# GPMC_GPMC_3B000000h register map
Vendor: Texas Instruments
Peripheral module from a debugger description file (folder am62D).
Registers are 32-bit, access per field, reset 0x0 unless marked. A register's access mark holds for its fields unless they carry their own. Offsets are as the file gives them; lines under a group give offsets from that group; [hi:lo] are bit positions; {n}, {i} and the like mark numbered series; 'fields as' and 'values as' point back to an identical list; <NAME> marks a mode.

## gpmc
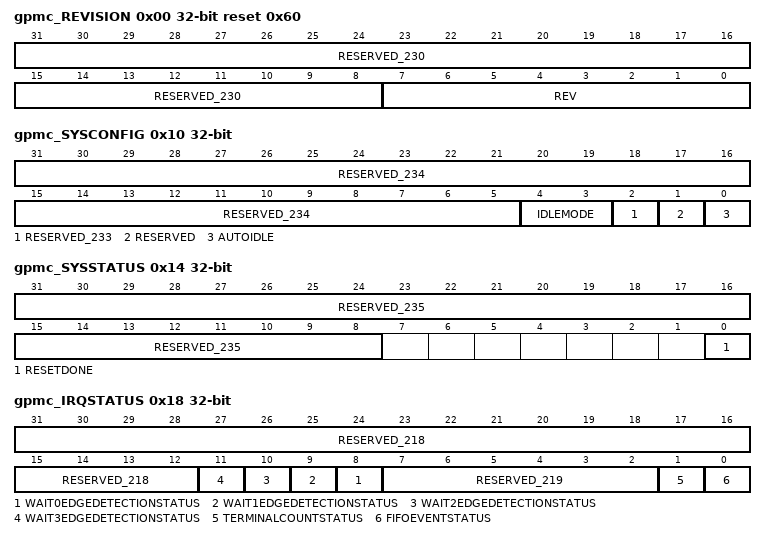
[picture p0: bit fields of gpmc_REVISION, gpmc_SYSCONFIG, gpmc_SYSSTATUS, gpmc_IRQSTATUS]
0x00 gpmc_REVISION ro reset 0x60 — This register contains the IP revision code
  [31:8] RESERVED_230 — Reads returns 0
  [7:0] REV — IP revision[7:4]Major revision[3:0]Minor revisionExamples: 0x10 for 1.0, 0x21 for 2.1 Reset Source: func_mod_g_arst_n
0x10 gpmc_SYSCONFIG — This register controls the various parameters of the OCP interface
  [31:5] RESERVED_234 ro — Write 0's for future compatibility Reads return 0
  [4:3] IDLEMODE rw — 0 Force-idle. An idle request is acknowledged unconditionally1 No-idle. An idle request is never acknowledged2 Smart-idle. Acknowledgement to an idle request is given based on the internal activity of the module3 reserved do not use
  [2] RESERVED_233 ro — Write 0 for future compatibility Reads returns 0
  [1] RESERVED rw — This bit must be kept 0 for normal functioning of the IP. Do not set this bit to 1 0 Normal mode1 The module is reset
  [0] AUTOIDLE rw — Internal OCP clock gating strategy 0 OCP clock is free-running1 Automatic OCP clock gating strategy is applied, based on the OCP interface activity
0x14 gpmc_SYSSTATUS ro — This register provides status information about the module, excluding the interrupt status information
  [31:8] RESERVED_235 — Reads returns 0
  [0] RESETDONE — Internal reset monitoring 0 Internal module reset in on-going1 Reset completed
0x18 gpmc_IRQSTATUS access not given — This interrupt status register regroups all the status of the module internal events that can generate an interrupt.
  [31:12] RESERVED_218 ro — Write 0's for future compatibility. Read returns 0
  [n+8] WAIT{n}EDGEDETECTIONSTATUS (n=0..3) — Status of the Wait{n} Edge Detection interrupt 0 Read 0: A transition on WAIT{n} input pin has not been detected0 Write 0: Wait{n}EdgeDetection status bit unchanged1 Read 1: A transition on WAIT{n} input pin has been detected1 Write 1: Wait{n}EdgeDetection status bit is reset (access R/W1TC)
  [7:2] RESERVED_219 ro — Write 0's for future compatibility. Read returns 0
  [1] TERMINALCOUNTSTATUS — Status of the TerminalCountEvent interrupt 0 Read 0: Indicates that CountValue is greater than 00 Write 0: TerminalCountEvent status bit unchanged1 Read 1: Indicates that CountValue is equal to 01 Write 1: TerminalCountEvent status bit is reset (access R/W1TC)
  [0] FIFOEVENTSTATUS — Status of the FIFOEvent interrupt 0 Read 0: Indicates than less than FIFOThreshold bytes are available in prefetch mode and less than FIFOThreshold bytes free places are available in write posting mode.0 Write 0: FIFOEvent status bit unchanged1 Read 1: Indicates than at least FIFOThreshold bytes are available in prefetch mode and at least FIFOThreshold bytes free places are available in write posting mode.1 Write 1: FIFOEvent status bit is reset (access R/W1TC)
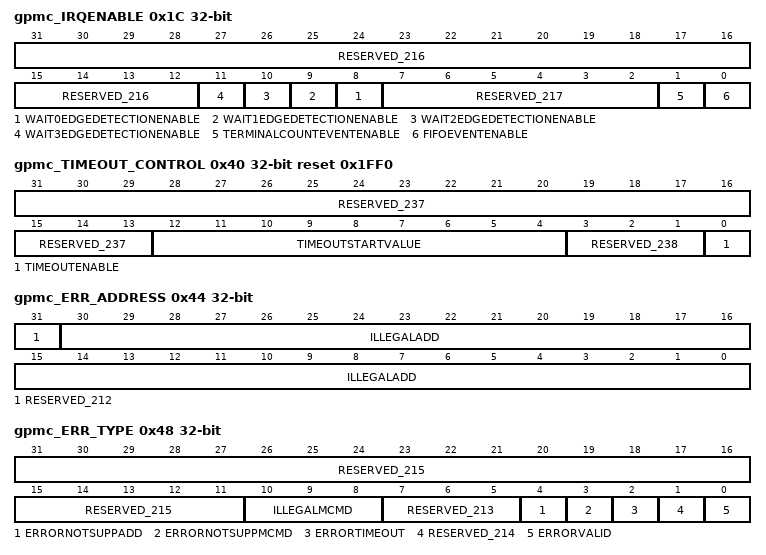
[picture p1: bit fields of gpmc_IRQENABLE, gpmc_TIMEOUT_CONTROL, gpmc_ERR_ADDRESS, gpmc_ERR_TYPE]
0x1C gpmc_IRQENABLE — The interrupt enable register allows to mask/unmask the module internal sources of interrupt, on a event-by-event basis.
  [31:12] RESERVED_216 ro — Write 0's for future compatibility. Read returns 0
  [n+8] WAIT{n}EDGEDETECTIONENABLE rw (n=0..3) — Enables the Wait{n} Edge Detection interrupt 0 Wait{n}EdgeDetection interrupt is masked1 Wait{n}EdgeDetection event generates an interrupt if occurs
  [7:2] RESERVED_217 ro — Write 0's for future compatibility. Read returns 0
  [1] TERMINALCOUNTEVENTENABLE rw — Enables TerminalCountEvent interrupt issuing in pre-fetch or write posting mode 0 TerminalCountEvent interrupt is masked1 TerminalCountEvent interrupt is not masked
  [0] FIFOEVENTENABLE rw — Enables the FIFOEvent interrupt 0 FIFOEvent interrupt is masked1 FIFOEvent interrupt is not masked
0x40 gpmc_TIMEOUT_CONTROL reset 0x1FF0 — The GPMC_TIMEOUT_CONTROL register allows the user to set the start value of the timeout counter
  [31:13] RESERVED_237 ro — Write 0's for future compatibility. Read returns 0
  [12:4] TIMEOUTSTARTVALUE rw — Start value of the time-out counter [0x000 corresponds to 0 GPMC.FCLK cycle, 0x001 corresponds to 1 GmpcClk cycle, &, 0x1FF corresponds to 511 GPMC.FCLK cyles.] Reset Source: func_mod_g_arst_n
  [3:1] RESERVED_238 ro — Write 0's for future compatibility. Read returns 0
  [0] TIMEOUTENABLE rw — Enable bit of the TimeOut feature 0 TimeOut feature is disabled1 TimeOut feature is enabled
0x44 gpmc_ERR_ADDRESS ro — The GPMC_ERR_ADDRESS register stores the address of the illegal access when an error occurs
  [31] RESERVED_212 — Write 0's for future compatibility. Read returns 0
  [30:0] ILLEGALADD — Address of illegal access : A30[0 for memory region, 1 for GPMC register region] and A29-A0[1 GBytes maximum] Reset Source: func_mod_g_arst_n
0x48 gpmc_ERR_TYPE access not given — The GPMC_ERR_TYPE register stores the type of error when an error occurs
  [31:11] RESERVED_215 ro — Write 0's for future compatibility. Read returns 0
  [10:8] ILLEGALMCMD ro — System Command of the transaction that caused the error Reset Source: func_mod_g_arst_n
  [7:5] RESERVED_213 ro — Write 0's for future compatibility. Read returns 0
  [4] ERRORNOTSUPPADD ro — Not supported Address error 0 No error occurs1 The error is due to a non supported Address
  [3] ERRORNOTSUPPMCMD ro — Not supported Command error 0 No error occurs1 The error is due to a non supported Command
  [2] ERRORTIMEOUT ro — Time-out error 0 No error occurs1 The error is due to a time out
  [1] RESERVED_214 ro — Write 0's for future compatibility. Read returns 0
  [0] ERRORVALID — Error validity status - Must be explicitely cleared with a write 1 transaction 0 All error fields no longer valid1 Error detected and logged in the other error fields (access R/W1TC)
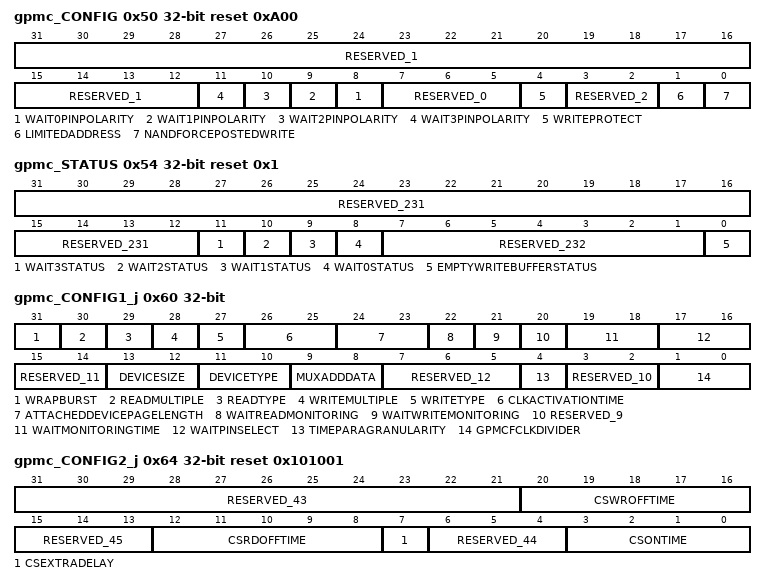
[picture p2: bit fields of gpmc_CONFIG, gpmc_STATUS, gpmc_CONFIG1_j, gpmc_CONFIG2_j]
0x50 gpmc_CONFIG reset 0xA00 — The configuration register allows global configuration of the GPMC
  [31:12] RESERVED_1 ro — Write 0's for future compatibility. Read returns 0
  [n+8] WAIT{n}PINPOLARITY rw (n=0..3) — Selects the polarity of input pin WAIT{n} 0 WAIT{n} active low1 WAIT{n} active high
  [7:5] RESERVED_0 ro — Write 0's for future compatibility. Read returns 0
  [4] WRITEPROTECT rw — Controls the WP output pin level 0 WP output pin is low1 WP output pin is high
  [3:2] RESERVED_2 ro — Write 0's for future compatibility. Read returns 0
  [1] LIMITEDADDRESS rw — Limited Address device support 0 No effect1 A26-A11 are not modified during an external memory access.
  [0] NANDFORCEPOSTEDWRITE rw — Enables the Force Posted Write feature to NAND Cmd/Add/Data location 0 Disables Force Posted Write1 Enables Force Posted Write
0x54 gpmc_STATUS ro reset 0x1 — The status register provides global status bits of the GPMC
  [31:12] RESERVED_231 — Write 0's for future compatibility. Read returns 0
  [11] WAIT3STATUS — Is a copy of input pin WAIT3. [Reset value is WAIT3 input pin sampled at IC reset] 0 WAIT3 de-asserted1 WAIT3 asserted
  [10] WAIT2STATUS — Is a copy of input pin WAIT2. [Reset value is WAIT2 input pin sampled at IC reset] 0 WAIT2 de-asserted1 WAIT2 asserted
  [9] WAIT1STATUS — Is a copy of input pin WAIT1. [Reset value is WAIT1 input pin sampled at IC reset] 0 WAIT1 de-asserted1 WAIT1 asserted
  [8] WAIT0STATUS — Is a copy of input pin WAIT0. [Reset value is WAIT0 input pin sampled at IC reset] 0 WAIT0 de-asserted1 WAIT0 asserted
  [7:1] RESERVED_232 — Write 0's for future compatibility Reads returns 0
  [0] EMPTYWRITEBUFFERSTATUS — Stores the empty status of the write buffer 0 Write Buffer is not empty1 Write Buffer is empty
0x60 gpmc_CONFIG1_j — The configuration 1 register sets signal control parameters per chip select
  [31] WRAPBURST rw — Enables the wrapping burst capability. Must be set if the attached device is configured in wrapping burst 0 Synchronous wrapping burst not supported1 Synchronous wrapping burst supported
  [30] READMULTIPLE rw — Selects the read single or multiple access 0 single access1 multiple access (burst if synchonous, page if asynchronous)
  [29] READTYPE rw — Selects the read mode operation 0 Read Asynchronous1 Read Synchronous
  [28] WRITEMULTIPLE rw — Selects the write single or multiple access 0 single access1 multiple access (burst if synchonous, considered as single if asynchronous)
  [27] WRITETYPE rw — Selects the write mode operation 0 Write Asynchronous1 Write Synchronous
  [26:25] CLKACTIVATIONTIME rw — Output GPMC.CLK activation time 0 First rising edge of GPMC.CLK at Start Access Time1 First rising edge of GPMC.CLK one GPMC.FCLK cycle after Start Access Time2 First rising edge of GPMC.CLK two GPMC.FCLK cycles after Start Access Time3 not defined
  [24:23] ATTACHEDDEVICEPAGELENGTH rw — Specifies the attached device page [burst] length 0 4 Words1 8 Words2 16 Words3 32 Words
  [22] WAITREADMONITORING rw — Selects the Wait monitoring configuration for Read accesses [Reset value is BOOTWAITEN input pin sampled at IC reset] 0 Wait pin is not monitored for read accesses1 Wait pin is monitored for read accesses
  [21] WAITWRITEMONITORING rw — Selects the Wait monitoring configuration for Write accesses 0 Wait pin is not monitored for write accesses1 Wait pin is monitored for write accesses
  [20] RESERVED_9 ro — Write 0's for future compatibility. Read returns 0
  [19:18] WAITMONITORINGTIME rw — Selects input pin Wait monitoring time 0 Wait pin is monitored with valid data1 Wait pin is monitored one GPMC.CLK cycle before valid data2 Wait pin is monitored two GPMC.CLK cycle before valid data3 not defined
  [17:16] WAITPINSELECT rw — Selects the input WAIT pin for this chip select [Reset value is BOOTWAITSELECT input pin sampled at IC reset for CS0 and 0 for CS1-7] 0 Wait input pin is WAIT01 Wait input pin is WAIT12 Wait input pin is WAIT23 Wait input pin is WAIT3
  [15:14] RESERVED_11 ro — Write 0's for future compatibility. Read returns 0
  [13:12] DEVICESIZE rw — Selects the device size attached [Reset value is BOOTDEVICESIZE input pin sampled at IC reset for CS0 and 01 for CS1-7] 0 8 bit1 16 bit2 32 bit3 reserved
  [11:10] DEVICETYPE rw — Selects the attached device type 0 NOR Flash, pSRAM, asynchronous devices1 reserved2 NAND Flash stream mode3 reserved
  [9:8] MUXADDDATA rw — Enables the Address and data multiplexed protocol [Reset value is CS0MUXDEVICE input pin sampled at IC reset for CS0 and 0 for CS1-7] 0 Non Multiplexed attached device1 AAD-Mux protocol device2 Address and data multiplexed attached device3 Reserved
  [7:5] RESERVED_12 ro — Write 0's for future compatibility. Read returns 0
  [4] TIMEPARAGRANULARITY rw — Signals timing latencies scalar factor [Rd/WRCycleTime, AccessTime, PageBurstAccessTime, CSOnTime, CSRd/WrOffTime, ADVOnTime, ADVRd/WrOffTime, OEOnTime, OEOffTime, WEOnTime, WEOffTime, Cycle2CycleDelay, BusTurnAround, TimeOutStartValue] 0 x1 latencies1 x2 latencies
  [3:2] RESERVED_10 ro — Write 0's for future compatibility. Read returns 0
  [1:0] GPMCFCLKDIVIDER rw — Divides the GPMC.FCLK clock 0 GPMC.CLK frequency = GPMC.FCLK frequency1 GPMC.CLK frequency = GPMC.FCLK frequency / 22 GPMC.CLK frequency = GPMC.FCLK frequency / 33 GPMC.CLK frequency = GPMC.FCLK frequency /4
0x64 gpmc_CONFIG2_j reset 0x101001 — Chip-select signal timing parameter configuration
  [31:21] RESERVED_43 ro — Write 0's for future compatibility Reads returns 0
  [20:16] CSWROFFTIME rw — CS# de-assertion time from start cycle time for write accesses [0x00 corresponds to 0 GPMC.FCLK cycle, 0x01 corresponds to 1 GPMC.FCLK cycle, &, 0x1F corresponds to 31 GPMC.FCLK cycles] Reset Source: func_mod_g_arst_n
  [15:13] RESERVED_45 ro — Write 0's for future compatibility. Read returns 0
  [12:8] CSRDOFFTIME rw — CS# de-assertion time from start cycle time for read accesses [0x00 corresponds to 0 GPMC.FCLK cycle, 0x01 corresponds to 1 GPMC.FCLK cycle, &, 0x1F corresponds to 31 GPMC.FCLK cycles] Reset Source: func_mod_g_arst_n
  [7] CSEXTRADELAY rw — CS# Add Extra Half GPMC.FCLK cycle 0 CS# Timing control signal is not delayed1 CS# Timing control signal is delayed of half GPMC.FCLK clock cycle
  [6:4] RESERVED_44 ro — Write 0's for future compatibility. Read returns 0
  [3:0] CSONTIME rw — CS# assertion time from start cycle time [0x0 corresponds to 0 GPMC.FCLK cycle, 0x1 corresponds to 1 GPMC.FCLK cycle, &, 0xF corresponds to 15 GPMC.FCLK cycles] Reset Source: func_mod_g_arst_n
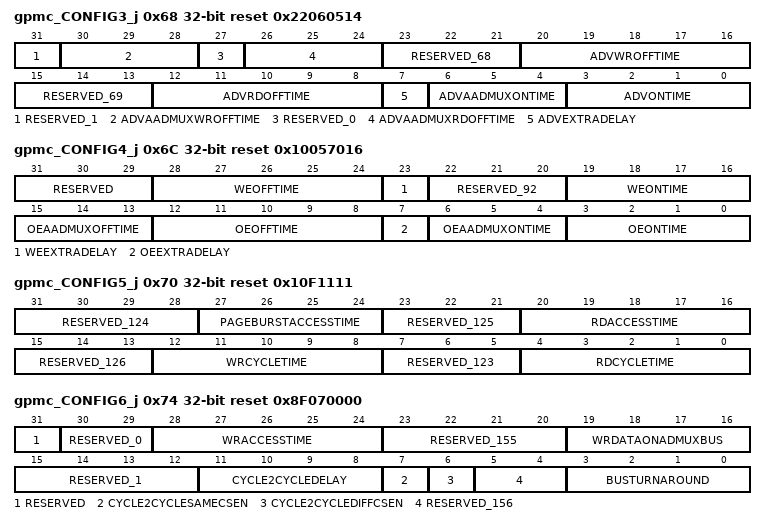
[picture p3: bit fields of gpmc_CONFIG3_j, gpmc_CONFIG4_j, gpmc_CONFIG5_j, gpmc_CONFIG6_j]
0x68 gpmc_CONFIG3_j reset 0x22060514 — ADV# signal timing parameter configuration
  [31] RESERVED_1 ro — Write 0's for future compatibility. Read returns 0
  [30:28] ADVAADMUXWROFFTIME rw — ADV# de-assertion for first address phase when using the AAD-Mux protocol Reset Source: func_mod_g_arst_n
  [27] RESERVED_0 ro — Write 0's for future compatibility. Read returns 0
  [26:24] ADVAADMUXRDOFFTIME rw — ADV# assertion for first address phase when using the AAD-Mux protocol Reset Source: func_mod_g_arst_n
  [23:21] RESERVED_68 ro — Write 0's for future compatibility. Read returns 0
  [20:16] ADVWROFFTIME rw — ADV# de-assertion time from start cycle time for write accesses [0x00 corresponds to 0 GPMC.FCLK cycle, 0x01 corresponds to 1 GPMC.FCLK cycle, &, 0x1F corresponds to 31 GPMC.FCLK cycles] Reset Source: func_mod_g_arst_n
  [15:13] RESERVED_69 ro — Write 0's for future compatibility. Read returns 0
  [12:8] ADVRDOFFTIME rw — ADV# de-assertion time from start cycle time for read accesses[0x00 corresponds to 0 GPMC.FCLK cycle, 0x01 corresponds to 1 GPMC.FCLK cycle, &, 0x1F corresponds to 31 GPMC.FCLK cycles] Reset Source: func_mod_g_arst_n
  [7] ADVEXTRADELAY rw — ADV# Add Extra Half GPMC.FCLK cycle 0 ADV# Timing control signal is not delayed1 ADV# Timing control signal is delayed of half GPMC.FCLK clock cycle
  [6:4] ADVAADMUXONTIME rw — ADV# assertion for first address phase when using the AAD-Mux protocol Reset Source: func_mod_g_arst_n
  [3:0] ADVONTIME rw — ADV# assertion time from start cycle time [0x0 corresponds to 0 GPMC.FCLK cycle, 0x1 corresponds to 1 GPMC.FCLK cycle, &, 0xF corresponds to 15 GPMC.FCLK cycles] Reset Source: func_mod_g_arst_n
0x6C gpmc_CONFIG4_j reset 0x10057016 — WE# and OE# signals timing parameter configuration
  [31:29] RESERVED ro — Write 0's for future compatibility. Read returns 0
  [28:24] WEOFFTIME rw — WE# de-assertion time from start cycle time [0x00 corresponds to 0 GPMC.FCLK cycle, 0x01 corresponds to 1 GPMC.FCLK cycle, &, 0x1F corresponds to 31 GPMC.FCLK cycles] Reset Source: func_mod_g_arst_n
  [23] WEEXTRADELAY rw — WE# Add Extra Half GPMC.FCLK cycle 0 WE# Timing control signal is not delayed1 WE# Timing control signal is delayed of half GPMC.FCLK clock cycle
  [22:20] RESERVED_92 ro — Write 0's for future compatibility. Read returns 0
  [19:16] WEONTIME rw — WE# assertion time from start cycle time [0x0 corresponds to 0 GPMC.FCLK cycle, 0x1 corresponds to 1 GPMC.FCLK cycle, &, 0xF corresponds to 15 GPMC.FCLK cycles] Reset Source: func_mod_g_arst_n
  [15:13] OEAADMUXOFFTIME rw — OE# de-assertion time for the first address phase in an AAD-Mux access Reset Source: func_mod_g_arst_n
  [12:8] OEOFFTIME rw — OE# de-assertion time from start cycle time [0x00 corresponds to 0 GPMC.FCLK cycle, 0x01 corresponds to 1 GPMC.FCLK cycle, &, 0x1F corresponds to 31 GPMC.FCLK cycles] Reset Source: func_mod_g_arst_n
  [7] OEEXTRADELAY rw — OE# Add Extra Half GPMC.FCLK cycle 0 OE# Timing control signal is not delayed1 OE# Timing control signal is delayed of half GPMC.FCLK clock cycle
  [6:4] OEAADMUXONTIME rw — OE# assertion time for the first address phase in an AAD-Mux access Reset Source: func_mod_g_arst_n
  [3:0] OEONTIME rw — OE# assertion time from start cycle time [0x0 corresponds to 0 GPMC.FCLK cycle, 0x1 corresponds to 1 GPMC.FCLK cycle, &, 0xF corresponds to 15 GPMC.FCLK cycles] Reset Source: func_mod_g_arst_n
0x70 gpmc_CONFIG5_j reset 0x10F1111 — RdAccessTime and CycleTime timing parameters configuration
  [31:28] RESERVED_124 ro — Write 0's for future compatibility. Read returns 0
  [27:24] PAGEBURSTACCESSTIME rw — Delay between successive words in a multiple access [0x0 corresponds to 0 GPMC.FCLK cycle, 0x1 corresponds to 1 GPMC.FCLK cycle, &, 0xF corresponds to 15 GPMC.FCLK cycles] Reset Source: func_mod_g_arst_n
  [23:21] RESERVED_125 ro — Write 0's for future compatibility. Read returns 0
  [20:16] RDACCESSTIME rw — Delay between start cycle time and first data valid [0x00 corresponds to 0 GPMC.FCLK cycle, 0x01 corresponds to 1 GPMC.FCLK cycle, &, 0x1F corresponds to 31 GPMC.FCLK cycles] Reset Source: func_mod_g_arst_n
  [15:13] RESERVED_126 ro — Write 0's for future compatibility Reads returns 0
  [12:8] WRCYCLETIME rw — Total write cycle time [0x00 corresponds to 0 GPMC.FCLK cycle, 0x01 corresponds to 1 GPMC.FCLK cycle, &, 0x1F corresponds to 31 GPMC.FCLK cycles] Reset Source: func_mod_g_arst_n
  [7:5] RESERVED_123 ro — Write 0's for future compatibility. Read returns 0
  [4:0] RDCYCLETIME rw — Total read cycle time [0x00 corresponds to 0 GPMC.FCLK cycle, 0x01 corresponds to 1 GPMC.FCLK cycle, &, 0x1F corresponds to 31 GPMC.FCLK cycles] Reset Source: func_mod_g_arst_n
0x74 gpmc_CONFIG6_j reset 0x8F070000 — WrAccessTime, WrDataOnADmuxBus, Cycle2Cycle and BusTurnAround parameters configuration
  [31] RESERVED rw — TI Internal use - Do not modify
  [30:29] RESERVED_0 ro — Write 0's for future compatibility. Read returns 0
  [28:24] WRACCESSTIME rw — Delay from StartAccessTime to the GPMC.FCLK rising edge corresponding the the GPMC.CLK rising edge used by the attached memory for the first data capture [0x00 corresponds to 0 GPMC.FCLK cycle, 0x01 corresponds to 1 GPMC.FCLK cycle, &, 0x1F corresponds to 31 GPMC.FCLK cycles] Reset Source: func_mod_g_arst_n
  [23:20] RESERVED_155 ro — Write 0's for future compatibility. Read returns 0
  [19:16] WRDATAONADMUXBUS rw — Specifies on which GPMC.FCLK rising edge the first data of the synchronous burst write is driven in the add/data mux bus Reset Source: func_mod_g_arst_n
  [15:12] RESERVED_1 ro — Write 0's for future compatibility. Read returns 0
  [11:8] CYCLE2CYCLEDELAY rw — Chip select high pulse delay between two successive accesses [0x0 corresponds to 0 GPMC.FCLK cycle, 0x1 corresponds to 1 GPMC.FCLK cycle, &, 0xF corresponds to 15 GPMC.FCLK cycles] Reset Source: func_mod_g_arst_n
  [7] CYCLE2CYCLESAMECSEN rw — Add Cycle2CycleDelay between two successive accesses to the same chip-select [any access type] 0 No delay between the two accesses1 Add Cycle2CycleDelay
  [6] CYCLE2CYCLEDIFFCSEN rw — Add Cycle2CycleDelay between two successive accesses to a different chip-select [any access type] 0 No delay between the two accesses1 Add Cycle2CycleDelay
  [5:4] RESERVED_156 ro — Write 0's for future compatibility Reads returns 0
  [3:0] BUSTURNAROUND rw — Bus turn around latency between two successive accesses to the same chip-select [rd to wr] or to a different chip-select [read to read and read to write] [0x0 corresponds to 0 GPMC.FCLK cycle, 0x1 corresponds to 1 GPMC.FCLK cycle, &, 0xF corresponds to 15 GPMC.FCLK cycles] Reset Source: func_mod_g_arst_n
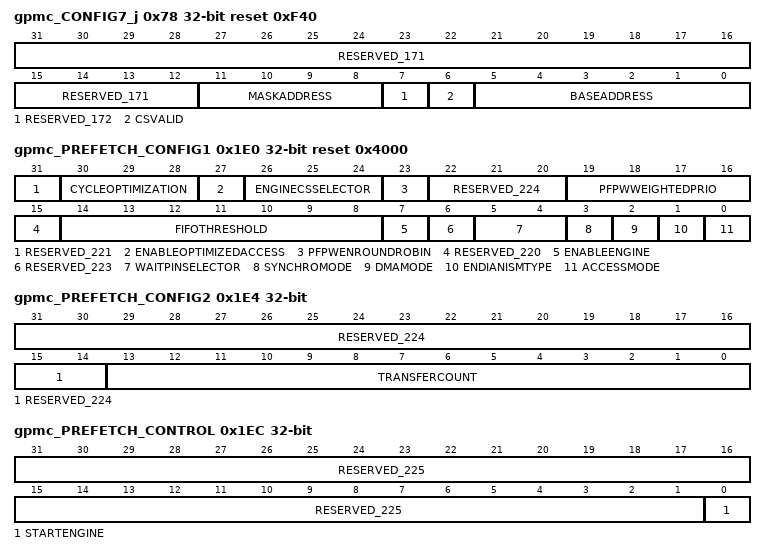
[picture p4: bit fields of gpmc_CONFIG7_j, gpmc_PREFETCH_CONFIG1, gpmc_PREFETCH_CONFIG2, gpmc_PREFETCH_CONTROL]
0x78 gpmc_CONFIG7_j reset 0xF40 — Chip-select address mapping configuration Note: For CS0, the register reset is 0xf40 while for all the other instances CS1-CS7, the reset is 0xf00.
  [31:12] RESERVED_171 ro — Write 0's for future compatibility. Read returns 0
  [11:8] MASKADDRESS rw — Chip-select mask address Reset Source: func_mod_g_arst_n
  [7] RESERVED_172 ro — Write 0's for future compatibility. Read returns 0
  [6] CSVALID rw — Chip-select enable [reset value is 1 for CS0 and 0 for CS1-7] 0 Chip-select disabled1 Chip-select enabled
  [5:0] BASEADDRESS rw — Chip-select base address Reset Source: func_mod_g_arst_n
0x7C gpmc_NAND_COMMAND_j wo — This Register is not a true register, just a address location.
  [31:0] GPMC_NAND_COMMAND_0 — Reset Source: func_mod_g_arst_n
0x80 gpmc_NAND_ADDRESS_j wo — This Register is not a true register, just a address location.
  [31:0] GPMC_NAND_ADDRESS_0 — Reset Source: func_mod_g_arst_n
0x84 gpmc_NAND_DATA_j rw — This Register is not a true register, just a address location.
  [31:0] GPMC_NAND_DATA_0 — Reset Source: func_mod_g_arst_n
0x1E0 gpmc_PREFETCH_CONFIG1 reset 0x4000 — Prefetch engine configuration 1
  [31] RESERVED_221 ro — Write 0's for future compatibility. Read returns 0
  [30:28] CYCLEOPTIMIZATION rw — Define the number of GPMC.FCLK cycles to be substracted from RdCycleTime, WrCycleTime, AccessTime, CSRdOffTime, CSWrOffTime, ADVRdOffTime, ADVWrOffTime, OEOffTime, WEOffTime [0x0 corresponds to 0 GPMC.FCLK cycle, 0x1 corresponds to 1 GPMC.FCLK cycle, &, 0x7 corresponds to 7 GPMC.FCLK cycles] Reset Source: func_mod_g_arst_n
  [27] ENABLEOPTIMIZEDACCESS rw — Enables access cycle optimization 0 Access cycle optimization is disabled1 Access cycle optimization is enabled
  [26:24] ENGINECSSELECTOR rw — Selects the CS where Prefetch Postwrite engine is active [0x0 corresponds toCS0, 0x1 corresponds to CS1, &, 0x7 corresponds to CS7] Reset Source: func_mod_g_arst_n
  [23] PFPWENROUNDROBIN rw — Enables the PFPW RoundRobin arbitration 0 Prefetch Postwrite engine round robin arbitration is disabled1 Prefetch Postwrite engine round robin arbitration is enabled
  [22:20] RESERVED_224 ro — Write 0's for future compatibility. Read returns 0
  [19:16] PFPWWEIGHTEDPRIO rw — When an arbitration occurs between a direct memory access and a PFPW engine access, the direct memory access is always serviced. If the PFPWEnRoundRobin is enabled, 0x0 means : the next access is granted to the PFPW engine, 0x1 means : the two next accesses are granted to the PFPW engine, ..., 0xF means : the 16 next accesses are granted to the PFPW engine. Reset Source: func_mod_g_arst_n
  [15] RESERVED_220 ro — Write 0's for future compatibility. Read returns 0
  [14:8] FIFOTHRESHOLD rw — Selects the maximum number of bytes read from the FIFO or written to the FIFO by the host on a DMA or interrupt request [0x00 corresponds to 0 byte, 0x01 corresponds to 1 byte, &, 0x40 corresponds to 64 bytes] Reset Source: func_mod_g_arst_n
  [7] ENABLEENGINE rw — Enables the Prefetch Postwite engine 0 Prefetch Postwrite engine is disabled1 Prefetch Postwrite engine is enabled
  [6] RESERVED_223 ro — Write 0's for future compatibility. Read returns 0
  [5:4] WAITPINSELECTOR rw — Select which wait pin edge detector should start the engine in synchronized mode 0 Selects Wait0EdgeDetection1 Selects Wait1EdgeDetection2 Selects Wait2EdgeDetection3 Selects Wait3EdgeDetection
  [3] SYNCHROMODE rw — Selects when the engine starts the access to CS 0 Engine starts the access to CS as soon as StartEngine is set1 Engine starts the access to CS as soon as StartEngine is set AND wait to non wait edge detection on the selected wait pin
  [2] DMAMODE rw — Selects interrupt synchronization or DMA request synchronization 0 Interrupt synchronization is enabled. Only interrupt line will be activated on FIFO threshold crossing.1 DMA request synchronization is enabled.A DMA request protocol is used.
  [1] ENDIANISMTYPE rw — Selects endianism for prefetch data [0x0 for Little Endian and 0x1 for Big Endian] Reset Source: func_mod_g_arst_n
  [0] ACCESSMODE rw — Selects pre-fetch read or write posting accesses 0 Pre-fetch read mode1 Write posting mode
0x1E4 gpmc_PREFETCH_CONFIG2 — Prefetch engine configuration 2
  [31:14] RESERVED_224 ro — Write 0's for future compatibility. Read returns 0
  [13:0] TRANSFERCOUNT rw — Selects the number of bytes to be read or written by the engine to the selected CS [0x0000 corresponds to 0 byte, 0x0001 corresponds to 1 byte, &, 0x2000 corresponds to 8 Kbytes] Reset Source: func_mod_g_arst_n
0x1EC gpmc_PREFETCH_CONTROL — Prefetch engine control
  [31:1] RESERVED_225 ro — Write 0's for future compatibility. Read returns 0
  [0] STARTENGINE rw — Resets the FIFO pointer and starts the engine 0 Write 0 stops the engine Read 0: engine is stopped1 Write 1 resets the FIFO pointer to 0x0 in prefetch mode and 0x40 in postwrite mode and starts the engine. Read 1: engine is running
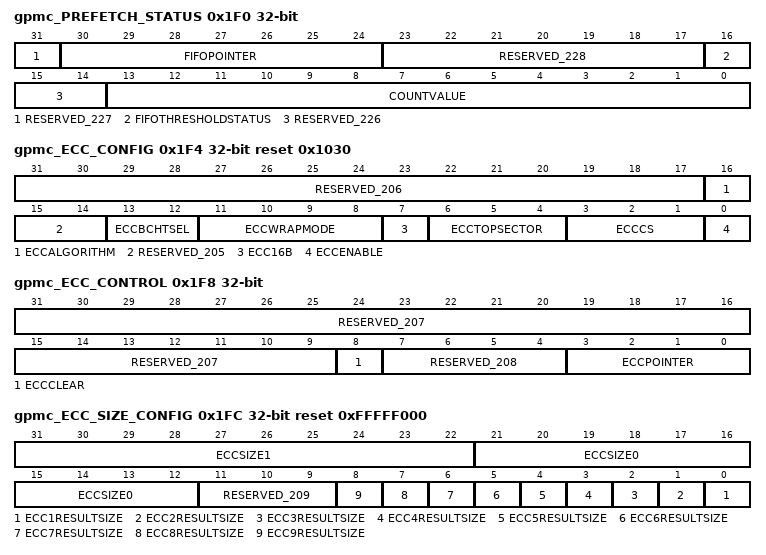
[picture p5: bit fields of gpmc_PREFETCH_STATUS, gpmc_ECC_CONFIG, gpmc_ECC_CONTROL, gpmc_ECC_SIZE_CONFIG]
0x1F0 gpmc_PREFETCH_STATUS ro — Prefetch engine status
  [31] RESERVED_227 — Write 0's for future compatibility. Read returns 0
  [30:24] FIFOPOINTER — Number of available bytes to be read or number of free empty byte places to be written [0x00 corresponds to 0 byte available to be read or 0 free empty place to be written, &, 0x40 corresponds to 64 bytes available to be read or 64 empty places to be written] Reset Source: func_mod_g_arst_n
  [23:17] RESERVED_228 — Write 0's for future compatibility. Read returns 0
  [16] FIFOTHRESHOLDSTATUS — Set when FIFOPointer exceeds FIFOThreshold value 0 FIFOPointer smaller or equal to FIFOThreshold. Writing to this bit has no effect1 FIFOPointer greater than FIFOThreshold. Writing to this bit has no effect
  [15:14] RESERVED_226 — Write 0's for future compatibility. Read returns 0
  [13:0] COUNTVALUE — Number of remaining bytes to be read or to be written by the engine according to the TransferCount value [0x0000 corresponds to 0 byte remaining to be read or to be written, 0x0001 corresponds to 1 byte remaining to be read or to be written, &, 0x2000 corresponds to 8 Kbytes remaining to be read or to be written] Reset Source: func_mod_g_arst_n
0x1F4 gpmc_ECC_CONFIG reset 0x1030 — ECC configuration
  [31:17] RESERVED_206 ro — Write 0's for future compatibility. Read returns 0
  [16] ECCALGORITHM rw — ECC algorithm used0x0: Hamming code0x1: BCH code Reset Source: func_mod_g_arst_n
  [15:14] RESERVED_205 ro — Write 0's for future compatibility. Read returns 0
  [13:12] ECCBCHTSEL rw — Error correction capability used for BCH0x0: up to 4 bits error correction [t = 4]0x1: up to 8 bits error correction [t=8]0x2: up to 16 bits error correction [t=16]0x3: reserved Reset Source: func_mod_g_arst_n
  [11:8] ECCWRAPMODE rw — Spare area organization definition for the BCH algorithm. See the BCH syndrome/parity calculator module functional specification for more details Reset Source: func_mod_g_arst_n
  [7] ECC16B rw — Selects an ECC calculated on 16 columns 0 ECC calculated on 8 columns1 ECC calculated on 16 columns
  [6:4] ECCTOPSECTOR rw — Number of sectors to process with the BCH algorithm0x0: 1 sector [512kB page]0x1: 2 sectors...0x3: 4 sectors [2kB page]...0x7: 8 sectors [4kB page] Reset Source: func_mod_g_arst_n
  [3:1] ECCCS rw — Selects the CS where ECC is computed 0 Chip select 01 Chip select 12 Chip select 23 Chip select 34 Chip select 45 Chip select 56 Chip select 67 Chip select 7
  [0] ECCENABLE rw — Enables the ECC feature 0 ECC disabled1 ECC enabled
0x1F8 gpmc_ECC_CONTROL access not given — ECC control
  [31:9] RESERVED_207 ro — Write 0's for future compatibility. Read returns 0
  [8] ECCCLEAR — Clear all ECC result registers [Reads returns 0 - Writes 1 to this field clear all ECC result registers - Writes 0 are ignored] Reset Source: func_mod_g_arst_n (access R/W1TC)
  [7:4] RESERVED_208 ro — Write 0's for future compatibility. Read returns 0
  [3:0] ECCPOINTER rw — Selects ECC result register [Reads to this field give the dynamic position of the ECC pointer - Writes to this field select the ECC result register where the first ECC computation will be stored]; Other enums: Writing other values disables the ECC engine [ECCEnable bit of GPMC_ECC_CONFIG set to 0] 0 writing 0000 disables the ECC engine (ECCEnable bit of GPMC_ECC_CONFIG set to 0)1 ECC result register 1 is selected2 ECC result register 2 is selected3 ECC result register 3 is selected4 ECC result register 4 is selected5 ECC result register 5 is selected6 ECC result register 6 is selected7 ECC result register 7 is selected8 ECC result register 8 is selected9 ECC result register 9 is selected
0x1FC gpmc_ECC_SIZE_CONFIG reset 0xFFFFF000 — ECC size
  [31:22] ECCSIZE1 rw — Defines ECC size 1 [For Hamming Code: 0x000 corresponds to 2 Bytes, 0x001 corresponds to 4 Bytes, 0x002 corresponds to 6 Bytes, 0x003 corresponds to 8 Bytes, &, 0x0FF corresponds to 512 Bytes. Max supported value is 0x0FF.] [For BCH: 0x000 corresponds to 0 nibbles, 0x001 corresponds to 1 nibble, 0x002 corresponds to 2 nibbles, 0x003 corresponds to 3 nibbles, &, 0x3FF corresponds to 1023 nibbles.] Reset Source: func_mod_g_arst_n
  [21:12] ECCSIZE0 rw — Defines ECC size 0 [For Hamming Code: 0x000 corresponds to 2 Bytes, 0x001 corresponds to 4 Bytes, 0x002 corresponds to 6 Bytes, 0x003 corresponds to 8 Bytes, &, 0x0FF corresponds to 512 Bytes. Max supported value is 0x0FF.] [For BCH: 0x000 corresponds to 0 nibbles, 0x001 corresponds to 1 nibble, 0x002 corresponds to 2 nibbles, 0x003 corresponds to 3 nibbles, &, 0x3FF corresponds to 1023 nibbles.] Reset Source: func_mod_g_arst_n
  [11:9] RESERVED_209 ro — Write 0's for future compatibility. Read returns 0
  [n-1] ECC{n}RESULTSIZE rw (n=1..9) — Selects ECC size for ECC {n} result register 0 ECCSize0 is selected1 ECCSize1 is selected
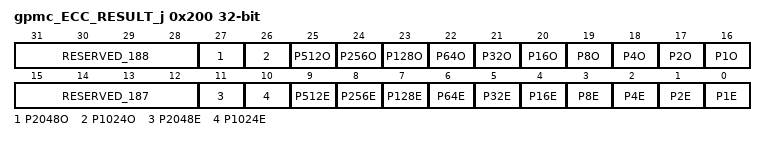
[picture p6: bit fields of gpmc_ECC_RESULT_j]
0x200 gpmc_ECC_RESULT_j ro — ECC result register
  [31:28] RESERVED_188 — Write 0's for future compatibility. Read returns 0
  [27] P2048O — Odd Row Parity bit 2048, only used for ECC computed on 512 Bytes Reset Source: func_mod_g_arst_n
  [26] P1024O — Odd Row Parity bit 1024 Reset Source: func_mod_g_arst_n
  [25] P512O — Odd Row Parity bit 512 Reset Source: func_mod_g_arst_n
  [24] P256O — Odd Row Parity bit 256 Reset Source: func_mod_g_arst_n
  [23] P128O — Odd Row Parity bit 128 Reset Source: func_mod_g_arst_n
  [22] P64O — Odd Row Parity bit 64 Reset Source: func_mod_g_arst_n
  [21] P32O — Odd Row Parity bit 32 Reset Source: func_mod_g_arst_n
  [20] P16O — Odd Row Parity bit 16 Reset Source: func_mod_g_arst_n
  [19] P8O — Odd Row Parity bit 8 Reset Source: func_mod_g_arst_n
  [18] P4O — Odd Column Parity bit 4 Reset Source: func_mod_g_arst_n
  [17] P2O — Odd Column Parity bit 2 Reset Source: func_mod_g_arst_n
  [16] P1O — Odd Column Parity bit 1 Reset Source: func_mod_g_arst_n
  [15:12] RESERVED_187 — Write 0's for future compatibility. Read returns 0
  [11] P2048E — Even Row Parity bit 2048, only used for ECC computed on 512 Bytes Reset Source: func_mod_g_arst_n
  [10] P1024E — Even Row Parity bit 1024 Reset Source: func_mod_g_arst_n
  [9] P512E — Even Row Parity bit 512 Reset Source: func_mod_g_arst_n
  [8] P256E — Even Row Parity bit 256 Reset Source: func_mod_g_arst_n
  [7] P128E — Even Row Parity bit 128 Reset Source: func_mod_g_arst_n
  [6] P64E — Even Row Parity bit 64 Reset Source: func_mod_g_arst_n
  [5] P32E — Even Row Parity bit 32 Reset Source: func_mod_g_arst_n
  [4] P16E — Even Row Parity bit 16 Reset Source: func_mod_g_arst_n
  [3] P8E — Even Row Parity bit 8 Reset Source: func_mod_g_arst_n
  [2] P4E — Even Column Parity bit 4 Reset Source: func_mod_g_arst_n
  [1] P2E — Even Column Parity bit 2 Reset Source: func_mod_g_arst_n
  [0] P1E — Even Column Parity bit 1 Reset Source: func_mod_g_arst_n
{0x240+4i} gpmc_BCH_RESULT_{i}_j ro (i=0..3) — BCH ECC result, bits {32i} to {32i+31}
  [31:0] BCH_RESULT_{i} — BCH ECC result, bits {32i} to {32i+31} Reset Source: func_mod_g_arst_n
0x2D0 gpmc_BCH_SWDATA wo — This register is used to directly pass data to the BCH ECC calculator without accessing the actual NAND flash interface.
  [15:0] BCH_DATA — Data to be included in the BCH calculation. Only bits 0 to 7 are taken into account if the calculator is configured to use 8 bits data [ECC16B = 0] Reset Source: func_mod_g_arst_n
0x300 gpmc_BCH_RESULT_4_j ro — BCH ECC result, bits 128 to 159
  [31:0] BCH_RESULT_4 — BCH ECC result, bits 128 to 159 Reset Source: func_mod_g_arst_n
0x304 gpmc_BCH_RESULT_5_j ro — BCH ECC result, bits 160 to 191
  [31:0] BCH_RESULT_5 — BCH ECC result, bits 160 to 191 Reset Source: func_mod_g_arst_n
0x308 gpmc_BCH_RESULT_6_j ro — BCH ECC result, bits 192 to 207
  [15:0] BCH_RESULT_6 — BCH ECC result, bits 192 to 207 Reset Source: func_mod_g_arst_n
